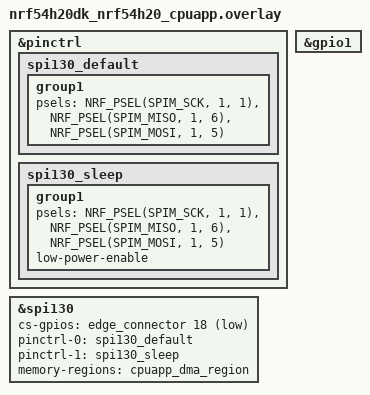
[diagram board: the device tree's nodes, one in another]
/*
 * Copyright (c) 2024 Nordic Semiconductor
 *
 * SPDX-License-Identifier: Apache-2.0
 */

#include "../nrf7002eb_interposer_p1_gpio_map_2.dtsi"

&pinctrl {
	spi130_default: spi130_default {
		group1 {
			psels = <NRF_PSEL(SPIM_SCK,  1, 1)>,
				<NRF_PSEL(SPIM_MISO, 1, 6)>,
				<NRF_PSEL(SPIM_MOSI, 1, 5)>;
		};
	};

	spi130_sleep: spi130_sleep {
		group1 {
			psels = <NRF_PSEL(SPIM_SCK,  1, 1)>,
				<NRF_PSEL(SPIM_MISO, 1, 6)>,
				<NRF_PSEL(SPIM_MOSI, 1, 5)>;
			low-power-enable;
		};
	};
};

edge_connector_spi: &spi130 {
	status = "okay";
	cs-gpios = <&edge_connector 18 GPIO_ACTIVE_LOW>;
	pinctrl-0 = <&spi130_default>;
	pinctrl-1 = <&spi130_sleep>;
	pinctrl-names = "default", "sleep";
	memory-regions = <&cpuapp_dma_region>;
};

&gpio1 {
	status = "okay";
};
